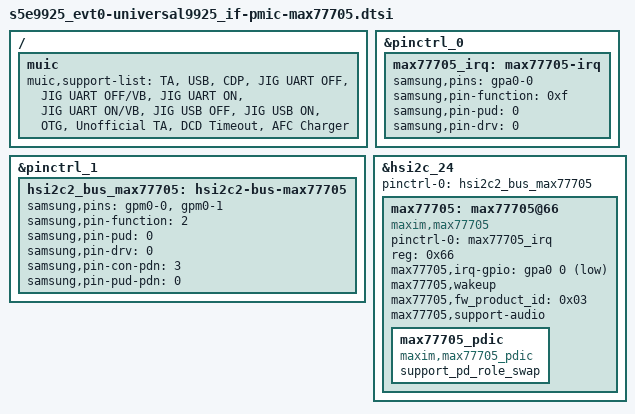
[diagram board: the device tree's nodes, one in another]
/* SAMSUNG UNIVERSAL2100 board device tree source
 *
 * Copyright (c) 2019 Samsung Electronics Co., Ltd.
 *		http://www.samsung.com
 *
 * This program is free software; you can redistribute it and/or modify
 * it under the terms of the GNU General Public License version 2 as
 * published by the Free Software Foundation.
 */

/ {
	fragment@muic {
		target-path = "/";
		__overlay__ {
			muic {
				status = "okay";
				muic,support-list = "TA","USB","CDP","JIG UART OFF","JIG UART OFF/VB",
					"JIG UART ON","JIG UART ON/VB","JIG USB OFF",
					"JIG USB ON","OTG","Unofficial TA","DCD Timeout",
					"AFC Charger";
			};
		};
	};
};

&pinctrl_0 {
	max77705_irq: max77705-irq {
		samsung,pins = "gpa0-0";
		samsung,pin-function = <0xf>;
		samsung,pin-pud = <0>;
		samsung,pin-drv = <0>;
	};
};

&pinctrl_1 {
	hsi2c2_bus_max77705: hsi2c2-bus-max77705 {
		samsung,pins = "gpm0-0", "gpm0-1";
		samsung,pin-function = <2>;
		samsung,pin-pud = <0>;
		samsung,pin-drv = <0>;
		samsung,pin-con-pdn = <3>;
		samsung,pin-pud-pdn = <0>;
	};
};

&hsi2c_24 {
	#address-cells = <1>;
	#size-cells = <0>;
	status = "okay";
	pinctrl-0 = <&hsi2c2_bus_max77705>;
	max77705: max77705@66 {
		compatible = "maxim,max77705";
		pinctrl-names = "default";
		pinctrl-0 = <&max77705_irq>;
		reg = <0x66>;
		max77705,irq-gpio = <&gpa0 0 1>;
		max77705,wakeup;
		max77705,fw_product_id = <0x03>;
		max77705,support-audio;
	};
};

&max77705 {
	max77705_pdic {
		status = "okay";
		compatible = "maxim,max77705_pdic";
		support_pd_role_swap;
	};
};

